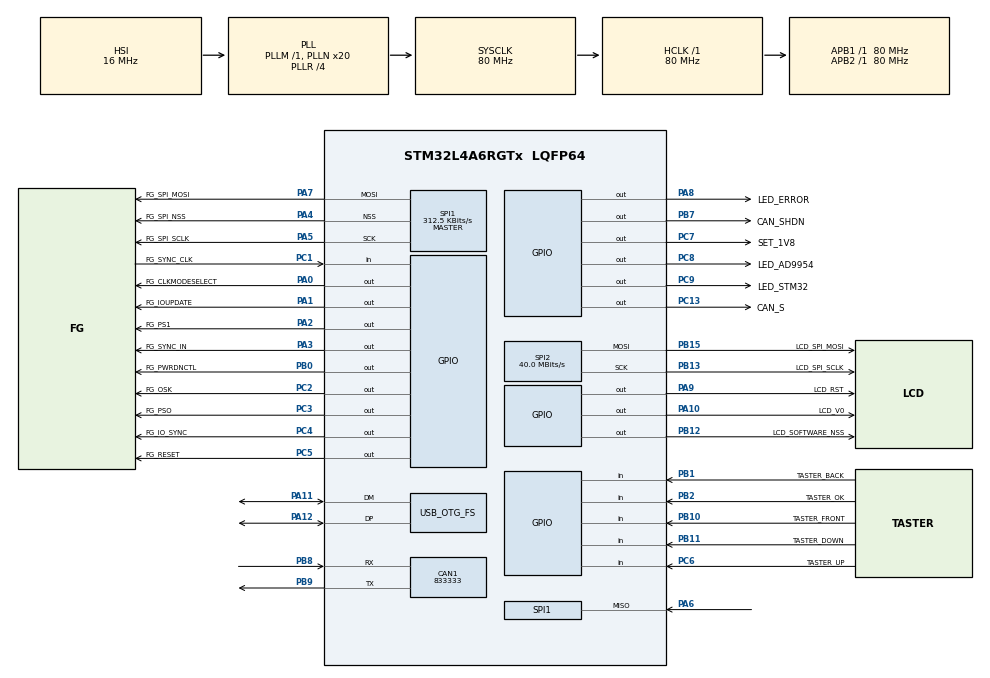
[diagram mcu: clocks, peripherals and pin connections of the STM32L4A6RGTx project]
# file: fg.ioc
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CAN1.BS1=CAN_BS1_4TQ
CAN1.BS2=CAN_BS2_1TQ
CAN1.CalculateBaudRate=833333
CAN1.CalculateTimeBit=1200.00
CAN1.CalculateTimeQuantum=200.0
FREERTOS.Mutexes01=AD9954_Data_Mutex,Dynamic,NULL
FREERTOS.Queues01=AD9954_readQueue,50,AD99554_message_struct_t,0,Dynamic,NULL,NULL;USB_CDC_Queue,256,uint8_t,0,Dynamic,NULL,NULL
FREERTOS.Tasks01=defaultTask,24,128,StartDefaultTask,Default,NULL,Dynamic,NULL,NULL;TaskUSB,8,4096,StartTastUSB,As external,NULL,Dynamic,NULL,NULL;TaskUser,8,4096,StartTaskUser,As external,NULL,Dynamic,NULL,NULL;TaskAD9954,8,4096,StartTaskAD9954,As external,NULL,Dynamic,NULL,NULL;TaskCAN,8,4096,StartTaskCAN,As external,NULL,Dynamic,NULL,NULL
FREERTOS.configTOTAL_HEAP_SIZE=131071
FREERTOS.configUSE_NEWLIB_REENTRANT=1
Mcu.Family=STM32L4
Mcu.Name=STM32L4A6RGTx
Mcu.Package=LQFP64
NVIC.OTG_FS_IRQn=true\:5\:0\:false\:false\:true\:true\:true\:true
NVIC.PriorityGroup=NVIC_PRIORITYGROUP_4
NVIC.SPI1_IRQn=true\:5\:0\:false\:false\:true\:true\:true\:true
NVIC.TIM1_UP_TIM16_IRQn=true\:0\:0\:false\:false\:true\:false\:false\:true
NVIC.TimeBase=TIM1_UP_TIM16_IRQn
NVIC.TimeBaseIP=TIM1
PA0.GPIO_Label=FG_CLKMODESELECT
PA0.Signal=GPIO_Output
PA1.GPIO_Label=FG_IOUPDATE
PA1.Signal=GPIO_Output
PA10.GPIO_Label=LCD_V0
PA10.Signal=GPIO_Output
PA11.Mode=Device_Only
PA11.Signal=USB_OTG_FS_DM
PA12.Mode=Device_Only
PA12.Signal=USB_OTG_FS_DP
PA13\ (JTMS/SWDIO).Mode=Serial_Wire
PA13\ (JTMS/SWDIO).Signal=SYS_JTMS-SWDIO
PA14\ (JTCK/SWCLK).Mode=Serial_Wire
PA14\ (JTCK/SWCLK).Signal=SYS_JTCK-SWCLK
PA2.GPIO_Label=FG_PS1
PA2.Signal=GPIO_Output
PA3.GPIO_Label=FG_SYNC_IN
PA3.Signal=GPIO_Output
PA4.GPIO_Label=FG_SPI_NSS
PA4.Mode=NSS_Signal_Hard_Output
PA4.Signal=SPI1_NSS
PA5.GPIO_Label=FG_SPI_SCLK
PA5.Mode=Full_Duplex_Master
PA5.Signal=SPI1_SCK
PA6.Mode=Full_Duplex_Master
PA6.Signal=SPI1_MISO
PA7.GPIO_Label=FG_SPI_MOSI
PA7.Mode=Full_Duplex_Master
PA7.Signal=SPI1_MOSI
PA8.GPIO_Label=LED_ERROR
PA8.Signal=GPIO_Output
PA9.GPIO_Label=LCD_RST
PA9.Signal=GPIO_Output
PB0.GPIO_Label=FG_PWRDNCTL
PB0.Signal=GPIO_Output
PB1.GPIO_Label=TASTER_BACK
PB1.GPIO_PuPd=GPIO_PULLUP
PB1.Signal=GPIO_Input
PB10.GPIO_Label=TASTER_FRONT
PB10.GPIO_PuPd=GPIO_PULLUP
PB10.Signal=GPIO_Input
PB11.GPIO_Label=TASTER_DOWN
PB11.GPIO_PuPd=GPIO_PULLUP
PB11.Signal=GPIO_Input
PB12.GPIO_Label=LCD_SOFTWARE_NSS
PB12.Signal=GPIO_Output
PB13.GPIO_Label=LCD_SPI_SCLK
PB13.Mode=TX_Only_Simplex_Unidirect_Master
PB13.Signal=SPI2_SCK
PB15.GPIO_Label=LCD_SPI_MOSI
PB15.Mode=TX_Only_Simplex_Unidirect_Master
PB15.Signal=SPI2_MOSI
PB2.GPIO_Label=TASTER_OK
PB2.GPIO_PuPd=GPIO_PULLUP
PB2.Signal=GPIO_Input
PB7.GPIO_Label=CAN_SHDN
PB7.Signal=GPIO_Output
PB8.Mode=CAN_Activate
PB8.Signal=CAN1_RX
PB9.Mode=CAN_Activate
PB9.Signal=CAN1_TX
PC1.GPIO_Label=FG_SYNC_CLK
PC1.Signal=GPIO_Input
PC13.GPIO_Label=CAN_S
PC13.Signal=GPIO_Output
PC2.GPIO_Label=FG_OSK
PC2.Signal=GPIO_Output
PC3.GPIO_Label=FG_PSO
PC3.Signal=GPIO_Output
PC4.GPIO_Label=FG_IO_SYNC
PC4.Signal=GPIO_Output
PC5.GPIO_Label=FG_RESET
PC5.Signal=GPIO_Output
PC6.GPIO_Label=TASTER_UP
PC6.GPIO_PuPd=GPIO_PULLUP
PC6.Signal=GPIO_Input
PC7.GPIO_Label=SET_1V8
PC7.Signal=GPIO_Output
PC8.GPIO_Label=LED_AD9954
PC8.Signal=GPIO_Output
PC9.GPIO_Label=LED_STM32
PC9.Signal=GPIO_Output
PH0-OSC_IN\ (PH0).Mode=HSE-External-Clock-Source
PH0-OSC_IN\ (PH0).Signal=RCC_OSC_IN
ProjectManager.HeapSize=0x4000
ProjectManager.StackSize=0x1000
ProjectManager.TargetToolchain=STM32CubeIDE
RCC.ADCFreq_Value=64000000
RCC.AHBFreq_Value=80000000
RCC.APB1Freq_Value=80000000
RCC.APB1TimFreq_Value=80000000
RCC.APB2Freq_Value=80000000
RCC.APB2TimFreq_Value=80000000
RCC.CK48CLockSelection=RCC_USBCLKSOURCE_HSI48
RCC.CortexFreq_Value=80000000
RCC.HCLKFreq_Value=80000000
RCC.HSE_VALUE=8000000
RCC.HSI48_VALUE=48000000
RCC.HSI_VALUE=16000000
RCC.LSE_VALUE=32768
RCC.MSI_VALUE=4000000
RCC.PLLN=20
RCC.PLLQ=RCC_PLLQ_DIV8
RCC.PLLR=RCC_PLLR_DIV4
RCC.PLLSourceVirtual=RCC_PLLSOURCE_HSI
RCC.SYSCLKFreq_VALUE=80000000
RCC.SYSCLKSource=RCC_SYSCLKSOURCE_PLLCLK
RCC.USBFreq_Value=48000000
RCC.VCOOutputFreq_Value=320000000
SPI1.BaudRatePrescaler=SPI_BAUDRATEPRESCALER_256
SPI1.CLKPolarity=SPI_POLARITY_LOW
SPI1.CalculateBaudRate=312.5 KBits/s
SPI1.DataSize=SPI_DATASIZE_8BIT
SPI1.Direction=SPI_DIRECTION_2LINES
SPI1.Mode=SPI_MODE_MASTER
SPI1.TIMode=SPI_TIMODE_DISABLE
SPI1.VirtualNSS=VM_NSSHARD
SPI1.VirtualType=VM_MASTER
SPI2.BaudRatePrescaler=SPI_BAUDRATEPRESCALER_2
SPI2.CalculateBaudRate=40.0 MBits/s
SPI2.DataSize=SPI_DATASIZE_8BIT
SPI2.Direction=SPI_DIRECTION_2LINES
SPI2.Mode=SPI_MODE_MASTER
SPI2.VirtualType=VM_MASTER
USB_DEVICE.CLASS_NAME_FS=CDC
USB_DEVICE.USBD_DEBUG_LEVEL=0
USB_DEVICE.USBD_LPM_ENABLED=0
USB_DEVICE.VirtualMode=Cdc
USB_DEVICE.VirtualModeFS=Cdc_FS
USB_OTG_FS.VirtualMode=Device_Only
VP_FREERTOS_VS_CMSIS_V2.Mode=CMSIS_V2
VP_SYS_VS_tim1.Mode=TIM1
VP_USB_DEVICE_VS_USB_DEVICE_CDC_FS.Mode=CDC_FS
board=custom

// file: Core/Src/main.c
/* USER CODE BEGIN Header */
/**
  ******************************************************************************
  * @file           : main.c
  * @brief          : Main program body
  ******************************************************************************
  * @attention
  *
  * <h2><center>&copy; Copyright (c) 2021 STMicroelectronics.
  * All rights reserved.</center></h2>
  *
  * This software component is licensed by ST under BSD 3-Clause license,
  * the "License"; You may not use this file except in compliance with the
  * License. You may obtain a copy of the License at:
  *                        opensource.org/licenses/BSD-3-Clause
  *
  ******************************************************************************
  */
/*
 * Wichtig wenn Can genutzt wird, dass der CAN Transreceiver
 * auch eine Spannungsversorgung hat. Wenn nicht anders irgendwie schon da,
 * dann den Jumper VBUS/3V3 stecken.
 */
/* USER CODE END Header */
#include "main.h"
#include "cmsis_os.h"
#include "can.h"
#include "spi.h"
#include "usb_device.h"
#include "gpio.h"

void SystemClock_Config(void);
void MX_FREERTOS_Init(void);

int main(void)
{

  /* MCU Configuration--------------------------------------------------------*/

  /* Reset of all peripherals, Initializes the Flash interface and the Systick. */
  HAL_Init();

  /* Configure the system clock */
  SystemClock_Config();

  /* Initialize all configured peripherals */
  MX_GPIO_Init();
  MX_CAN1_Init();
  MX_SPI1_Init();
  MX_SPI2_Init();

  /* Init scheduler */
  osKernelInitialize();  /* Call init function for freertos objects (in freertos.c) */
  MX_FREERTOS_Init();
  /* Start scheduler */
  osKernelStart();

  /* We should never get here as control is now taken by the scheduler */
  /* Infinite loop */
  while (1)
  {

  }
}

void SystemClock_Config(void)
{
  RCC_OscInitTypeDef RCC_OscInitStruct = {0};
  RCC_ClkInitTypeDef RCC_ClkInitStruct = {0};

  /** Configure the main internal regulator output voltage
  */
  if (HAL_PWREx_ControlVoltageScaling(PWR_REGULATOR_VOLTAGE_SCALE1) != HAL_OK)
  {
    Error_Handler();
  }
  /** Initializes the RCC Oscillators according to the specified parameters
  * in the RCC_OscInitTypeDef structure.
  */
  RCC_OscInitStruct.OscillatorType = RCC_OSCILLATORTYPE_HSI48|RCC_OSCILLATORTYPE_HSI;
  RCC_OscInitStruct.HSIState = RCC_HSI_ON;
  RCC_OscInitStruct.HSI48State = RCC_HSI48_ON;
  RCC_OscInitStruct.HSICalibrationValue = RCC_HSICALIBRATION_DEFAULT;
  RCC_OscInitStruct.PLL.PLLState = RCC_PLL_ON;
  RCC_OscInitStruct.PLL.PLLSource = RCC_PLLSOURCE_HSI;
  RCC_OscInitStruct.PLL.PLLM = 1;
  RCC_OscInitStruct.PLL.PLLN = 20;
  RCC_OscInitStruct.PLL.PLLP = RCC_PLLP_DIV2;
  RCC_OscInitStruct.PLL.PLLQ = RCC_PLLQ_DIV8;
  RCC_OscInitStruct.PLL.PLLR = RCC_PLLR_DIV4;
  if (HAL_RCC_OscConfig(&RCC_OscInitStruct) != HAL_OK)
  {
    Error_Handler();
  }
  /** Initializes the CPU, AHB and APB buses clocks
  */
  RCC_ClkInitStruct.ClockType = RCC_CLOCKTYPE_HCLK|RCC_CLOCKTYPE_SYSCLK
                              |RCC_CLOCKTYPE_PCLK1|RCC_CLOCKTYPE_PCLK2;
  RCC_ClkInitStruct.SYSCLKSource = RCC_SYSCLKSOURCE_PLLCLK;
  RCC_ClkInitStruct.AHBCLKDivider = RCC_SYSCLK_DIV1;
  RCC_ClkInitStruct.APB1CLKDivider = RCC_HCLK_DIV1;
  RCC_ClkInitStruct.APB2CLKDivider = RCC_HCLK_DIV1;

  if (HAL_RCC_ClockConfig(&RCC_ClkInitStruct, FLASH_LATENCY_4) != HAL_OK)
  {
    Error_Handler();
  }
}

void HAL_TIM_PeriodElapsedCallback(TIM_HandleTypeDef *htim)
{
  if (htim->Instance == TIM1) {
    HAL_IncTick();
  }
}

void Error_Handler(void)
{
  __disable_irq();
  while (1)
  {
  }
}

/************************ (C) COPYRIGHT STMicroelectronics *****END OF FILE****/

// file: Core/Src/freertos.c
/* USER CODE BEGIN Header */
/**
  ******************************************************************************
  * File Name          : freertos.c
  * Description        : Code for freertos applications
  ******************************************************************************
  * @attention
  *
  * <h2><center>&copy; Copyright (c) 2021 STMicroelectronics.
  * All rights reserved.</center></h2>
  *
  * This software component is licensed by ST under Ultimate Liberty license
  * SLA0044, the "License"; You may not use this file except in compliance with
  * the License. You may obtain a copy of the License at:
  *                             www.st.com/SLA0044
  *
  ******************************************************************************
  */
/* USER CODE END Header */

#include "FreeRTOS.h"
#include "task.h"
#include "main.h"
#include "cmsis_os.h"

/* USER CODE BEGIN Includes */
#include "AD9954.h"
/* USER CODE END Includes */

/* Definitions for defaultTask */
osThreadId_t defaultTaskHandle;
const osThreadAttr_t defaultTask_attributes = {
  .name = "defaultTask",
  .stack_size = 128 * 4,
  .priority = (osPriority_t) osPriorityNormal,
};
/* Definitions for TaskUSB */
osThreadId_t TaskUSBHandle;
const osThreadAttr_t TaskUSB_attributes = {
  .name = "TaskUSB",
  .stack_size = 4096 * 4,
  .priority = (osPriority_t) osPriorityLow,
};
/* Definitions for TaskUser */
osThreadId_t TaskUserHandle;
const osThreadAttr_t TaskUser_attributes = {
  .name = "TaskUser",
  .stack_size = 4096 * 4,
  .priority = (osPriority_t) osPriorityLow,
};
/* Definitions for TaskAD9954 */
osThreadId_t TaskAD9954Handle;
const osThreadAttr_t TaskAD9954_attributes = {
  .name = "TaskAD9954",
  .stack_size = 4096 * 4,
  .priority = (osPriority_t) osPriorityLow,
};
/* Definitions for TaskCAN */
osThreadId_t TaskCANHandle;
const osThreadAttr_t TaskCAN_attributes = {
  .name = "TaskCAN",
  .stack_size = 4096 * 4,
  .priority = (osPriority_t) osPriorityLow,
};
/* Definitions for AD9954_readQueue */
osMessageQueueId_t AD9954_readQueueHandle;
const osMessageQueueAttr_t AD9954_readQueue_attributes = {
  .name = "AD9954_readQueue"
};
/* Definitions for USB_CDC_Queue */
osMessageQueueId_t USB_CDC_QueueHandle;
const osMessageQueueAttr_t USB_CDC_Queue_attributes = {
  .name = "USB_CDC_Queue"
};
/* Definitions for AD9954_Data_Mutex */
osMutexId_t AD9954_Data_MutexHandle;
const osMutexAttr_t AD9954_Data_Mutex_attributes = {
  .name = "AD9954_Data_Mutex"
};

void StartDefaultTask(void *argument);
extern void StartTastUSB(void *argument);
extern void StartTaskUser(void *argument);
extern void StartTaskAD9954(void *argument);
extern void StartTaskCAN(void *argument);

extern void MX_USB_DEVICE_Init(void);
void MX_FREERTOS_Init(void); /* (MISRA C 2004 rule 8.1) */

void MX_FREERTOS_Init(void) {
  /* Create the mutex(es) */
  /* creation of AD9954_Data_Mutex */
  AD9954_Data_MutexHandle = osMutexNew(&AD9954_Data_Mutex_attributes);

  /* Create the queue(s) */
  /* creation of AD9954_readQueue */
  AD9954_readQueueHandle = osMessageQueueNew (50, sizeof(AD99554_message_struct_t), &AD9954_readQueue_attributes);

  /* creation of USB_CDC_Queue */
  USB_CDC_QueueHandle = osMessageQueueNew (256, sizeof(uint8_t), &USB_CDC_Queue_attributes);

  /* Create the thread(s) */
  /* creation of defaultTask */
  defaultTaskHandle = osThreadNew(StartDefaultTask, NULL, &defaultTask_attributes);

  /* creation of TaskUSB */
  TaskUSBHandle = osThreadNew(StartTastUSB, NULL, &TaskUSB_attributes);

  /* creation of TaskUser */
  TaskUserHandle = osThreadNew(StartTaskUser, NULL, &TaskUser_attributes);

  /* creation of TaskAD9954 */
  TaskAD9954Handle = osThreadNew(StartTaskAD9954, NULL, &TaskAD9954_attributes);

  /* creation of TaskCAN */
  TaskCANHandle = osThreadNew(StartTaskCAN, NULL, &TaskCAN_attributes);

}

void StartDefaultTask(void *argument)
{
  /* init code for USB_DEVICE */
  MX_USB_DEVICE_Init();
  for(;;)
  {
    osDelay(1);
  }
}

/************************ (C) COPYRIGHT STMicroelectronics *****END OF FILE****/
